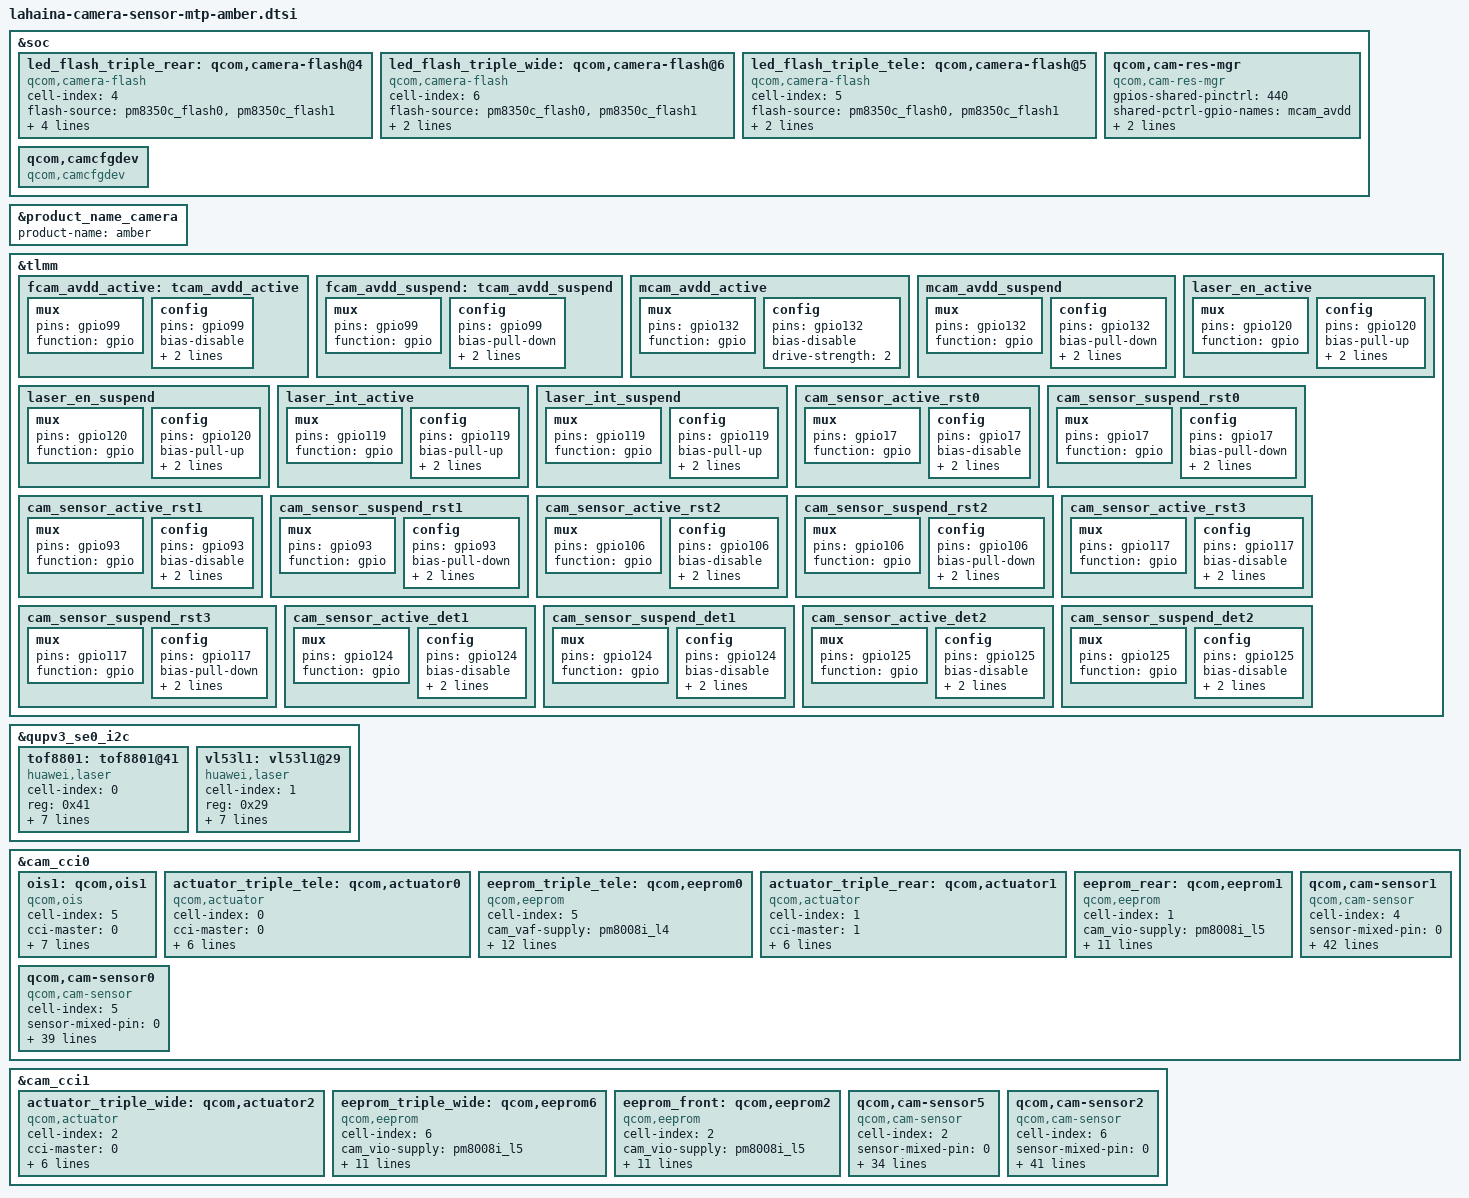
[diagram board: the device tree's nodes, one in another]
#include <dt-bindings/clock/qcom,camcc-lahaina.h>

&soc {
	led_flash_triple_rear: qcom,camera-flash@4 {
		cell-index = <4>;
		compatible = "qcom,camera-flash";
		flash-source = <&pm8350c_flash0 &pm8350c_flash1>;
		torch-source = <&pm8350c_torch0 &pm8350c_torch1>;
		switch-source = <&pm8350c_switch2>;
		torch-light-num = <0 1>;
		torch-light-name = "torch-light0", "torch-light1";
		status = "ok";
	};

	led_flash_triple_wide: qcom,camera-flash@6 {
		cell-index = <6>;
		compatible = "qcom,camera-flash";
		flash-source = <&pm8350c_flash0 &pm8350c_flash1>;
		torch-source = <&pm8350c_torch0 &pm8350c_torch1>;
		switch-source = <&pm8350c_switch2>;
		status = "ok";
	};

	led_flash_triple_tele: qcom,camera-flash@5 {
		cell-index = <5>;
		compatible = "qcom,camera-flash";
		flash-source = <&pm8350c_flash0 &pm8350c_flash1>;
		torch-source = <&pm8350c_torch0 &pm8350c_torch1>;
		switch-source = <&pm8350c_switch2>;
		status = "ok";
	};

    qcom,cam-res-mgr {
         compatible = "qcom,cam-res-mgr";
         gpios-shared-pinctrl = <440>;
         shared-pctrl-gpio-names = "mcam_avdd";
         pinctrl-names = "mcam_avdd_active", "mcam_avdd_suspend";
         pinctrl-0 = <&mcam_avdd_active>;
         pinctrl-1 = <&mcam_avdd_suspend>;
         status = "ok";
    };

	qcom,camcfgdev {
		compatible = "qcom,camcfgdev";
		status = "ok";
	};
};

&product_name_camera {
    product-name = "amber";
};

&tlmm {
	fcam_avdd_active: tcam_avdd_active {
		/* AVDD for font */
		mux {
			pins = "gpio99";
			function = "gpio";
		};

		config {
			pins = "gpio99";
			bias-disable; /* No PULL */
			drive-strength = <2>; /* 2 MA */
			output-high;
		};
	};

	fcam_avdd_suspend: tcam_avdd_suspend {
		/* AVDD for font */
		mux {
			pins = "gpio99";
			function = "gpio";
		};

		config {
			pins = "gpio99";
			bias-pull-down; /* PULL DOWN */
			drive-strength = <2>; /* 2 MA */
			output-low;
		};
	};
	mcam_avdd_active: mcam_avdd_active {
		/* mcam_avdd */
		mux {
			pins = "gpio132";
			function = "gpio";
		};

		config {
			pins = "gpio132";
			bias-disable; /* No PULL */
			drive-strength = <2>; /* 2 MA */
		};
	};

	mcam_avdd_suspend: mcam_avdd_suspend {
		/* mcam_avdd */
		mux {
			pins = "gpio132";
			function = "gpio";
		};

		config {
			pins = "gpio132";
			bias-pull-down; /* PULL DOWN */
			drive-strength = <2>; /* 2 MA */
			output-low;
		};
	};

	laser_en_active: laser_en_active {
		/* laser en pin */
		mux {
			pins = "gpio120";
			function = "gpio";
		};

		config {
			pins = "gpio120";
			bias-pull-up; /* PULL UP */
			drive-strength = <2>; /* 2 MA */
			input-enable;
		};
	};

	laser_en_suspend: laser_en_suspend {
		/* laser en pin */
		mux {
			pins = "gpio120";
			function = "gpio";
		};

		config {
			pins = "gpio120";
			bias-pull-up; /* PULL UP */
			drive-strength = <2>; /* 2 MA */
			input-enable;
		};
	};

	laser_int_active: laser_int_active {
		/* laser int pin */
		mux {
			pins = "gpio119";
			function = "gpio";
		};

		config {
			pins = "gpio119";
			bias-pull-up; /* PULL UP */
			drive-strength = <2>; /* 2 MA */
			input-enable;
		};
	};

	laser_int_suspend: laser_int_suspend {
		/* laser int pin */
		mux {
			pins = "gpio119";
			function = "gpio";
		};

		config {
			pins = "gpio119";
			bias-pull-up; /* PULL UP */
			drive-strength = <2>; /* 2 MA */
			input-enable;
		};
	};

	cam_sensor_active_rst0: cam_sensor_active_rst0 {
		/* RESET REAR */
		mux {
			pins = "gpio17";
			function = "gpio";
		};

		config {
			pins = "gpio17";
			bias-disable; /* No PULL */
			drive-strength = <2>; /* 2 MA */
			input-enable;
		};
	};

	cam_sensor_suspend_rst0: cam_sensor_suspend_rst0 {
		/* RESET REAR */
		mux {
			pins = "gpio17";
			function = "gpio";
		};

		config {
			pins = "gpio17";
			bias-pull-down; /* PULL DOWN */
			drive-strength = <2>; /* 2 MA */
			output-low;
		};
	};

	cam_sensor_active_rst1: cam_sensor_active_rst1 {
		/* RESET REARAUX */
		mux {
			pins = "gpio93";
			function = "gpio";
		};

		config {
			pins = "gpio93";
			bias-disable; /* No PULL */
			drive-strength = <2>; /* 2 MA */
			input-enable;
		};
	};

	cam_sensor_suspend_rst1: cam_sensor_suspend_rst1 {
		/* RESET REARAUX */
		mux {
			pins = "gpio93";
			function = "gpio";
		};

		config {
			pins = "gpio93";
			bias-pull-down; /* PULL DOWN */
			drive-strength = <2>; /* 2 MA */
			output-low;
		};
	};

	cam_sensor_active_rst2: cam_sensor_active_rst2 {
		/* RESET 2 */
		mux {
			pins = "gpio106";
			function = "gpio";
		};

		config {
			pins = "gpio106";
			bias-disable; /* No PULL */
			drive-strength = <2>; /* 2 MA */
			input-enable;
		};
	};

	cam_sensor_suspend_rst2: cam_sensor_suspend_rst2 {
		/* RESET 2 */
		mux {
			pins = "gpio106";
			function = "gpio";
		};

		config {
			pins = "gpio106";
			bias-pull-down; /* PULL DOWN */
			drive-strength = <2>; /* 2 MA */
			output-low;
		};
	};

	cam_sensor_active_rst3: cam_sensor_active_rst3 {
		/* RESET 3 */
		mux {
			pins = "gpio117";
			function = "gpio";
		};

		config {
			pins = "gpio117";
			bias-disable; /* No PULL */
			drive-strength = <2>; /* 2 MA */
			input-enable;
		};
	};

	cam_sensor_suspend_rst3: cam_sensor_suspend_rst3 {
		/* RESET 3 */
		mux {
			pins = "gpio117";
			function = "gpio";
		};

		config {
			pins = "gpio117";
			bias-pull-down; /* PULL DOWN */
			drive-strength = <2>; /* 2 MA */
			output-low;
		};
	};

	cam_sensor_active_det1: cam_sensor_active_det1 {
		/* BTB_DET 1 */
		mux {
			pins = "gpio124";
			function = "gpio";
		};

		config {
			pins = "gpio124";
			bias-disable; /* No PULL */
			drive-strength = <2>; /* 2 MA */
			input-enable;
		};
	};

	cam_sensor_suspend_det1: cam_sensor_suspend_det1 {
		/* BTB_DET 1 */
		mux {
			pins = "gpio124";
			function = "gpio";
		};

		config {
			pins = "gpio124";
			bias-disable; /* No PULL */
			drive-strength = <2>; /* 2 MA */
			input-enable;
		};
	};

	cam_sensor_active_det2: cam_sensor_active_det2 {
		/* BTB_DET 2 */
		mux {
			pins = "gpio125";
			function = "gpio";
		};

		config {
			pins = "gpio125";
			bias-disable; /* No PULL */
			drive-strength = <2>; /* 2 MA */
			input-enable;
		};
	};

	cam_sensor_suspend_det2: cam_sensor_suspend_det2 {
		/* BTB_DET 2 */
		mux {
			pins = "gpio125";
			function = "gpio";
		};

		config {
			pins = "gpio125";
			bias-disable; /* No PULL */
			drive-strength = <2>; /* 2 MA */
			input-enable;
		};
	};
};

/* laser */
&qupv3_se0_i2c {
	status = "ok";

	tof8801: tof8801@41 {
		cell-index = <0>;
		compatible = "huawei,laser";
		reg = <0x41>;
		vdd_ana-supply = <&pm8350_l7>;
		gpios = <&tlmm 120 0>,
			<&tlmm 119 0>;
		pinctrl-names = "laser_int_active", "laser_en_active";
		pinctrl-0 = <&laser_int_active>;
		pinctrl-1 = <&laser_en_active>;
		gpio-req-tbl-num = <0>;
		gpio-req-tbl-flags = <0>;
		gpio-req-tbl-label = "CAM_VAF0";
		status = "ok";
	};

	vl53l1: vl53l1@29 {
		cell-index = <1>;
		compatible = "huawei,laser";
		reg = <0x29>;
		vdd_ana-supply = <&pm8350_l7>;
		gpios = <&tlmm 120 0>,
			<&tlmm 119 0>;
		pinctrl-names = "laser_int_active", "laser_en_active";
		pinctrl-0 = <&laser_int_active>;
		pinctrl-1 = <&laser_en_active>;
		gpio-req-tbl-num = <0>;
		gpio-req-tbl-flags = <0>;
		gpio-req-tbl-label = "CAM_VAF0";
		status = "ok";
	};
};

/* cci0: i2c0 i2c1 */
&cam_cci0 {

	ois1: qcom,ois1 {
		cell-index = <5>;
		compatible = "qcom,ois";
		cci-master = <0>;
		cam_vio-supply = <&pm8008i_l5>;
		cam_vaf-supply = <&pm8008i_l4>;
		regulator-names = "cam_vio", "cam_vaf";
		rgltr-cntrl-support;
		rgltr-min-voltage = <1800000 3200000>;
		rgltr-max-voltage = <1900000 3200000>;
		rgltr-load-current = <74000 103000>;
	};

	actuator_triple_tele: qcom,actuator0 {
		cell-index = <0>;
		compatible = "qcom,actuator";
		cci-master = <0>;
		cam_vaf-supply = <&pm8008i_l4>;
		regulator-names = "cam_vaf";
		rgltr-cntrl-support;
		rgltr-min-voltage = <3200000>;
		rgltr-max-voltage = <3200000>;
		rgltr-load-current = <103000>;
	};

	eeprom_triple_tele: qcom,eeprom0 {
		cell-index = <5>;
		compatible = "qcom,eeprom";
		cam_vaf-supply = <&pm8008i_l4>;
		cam_vio-supply = <&pm8008i_l5>;
		cam_clk-supply = <&cam_cc_titan_top_gdsc>;
		regulator-names = "cam_vaf", "cam_vio", "cam_clk";
		rgltr-cntrl-support;
		rgltr-min-voltage = <3200000 1800000 0>;
		rgltr-max-voltage = <3200000 1900000 0>;
		rgltr-load-current = <103000 74000 0>;
		gpio-no-mux = <0>;
		cci-master = <0>;
		status = "ok";
		clocks = <&clock_camcc CAM_CC_MCLK0_CLK>;
		clock-names = "cam_clk";
		clock-cntl-level = "nominal";
		clock-rates = <19200000>;
	};

	actuator_triple_rear: qcom,actuator1 {
		cell-index = <1>;
		compatible = "qcom,actuator";
		cci-master = <1>;
		cam_vaf-supply = <&pm8008i_l4>;
		regulator-names = "cam_vaf";
		rgltr-cntrl-support;
		rgltr-min-voltage = <3200000>;
		rgltr-max-voltage = <3200000>;
		rgltr-load-current = <103000>;
	};

	eeprom_rear: qcom,eeprom1 {
		cell-index = <1>;
		compatible = "qcom,eeprom";
		cam_vio-supply = <&pm8008i_l5>;
		cam_clk-supply = <&cam_cc_titan_top_gdsc>;
		regulator-names = "cam_vio", "cam_clk";
		rgltr-cntrl-support;
		rgltr-min-voltage = <1800000 0>;
		rgltr-max-voltage = <1800000 0>;
		rgltr-load-current = <74000 0>;
		gpio-no-mux = <0>;
		cci-master = <1>; /* i2c1 */
		status = "ok";
		clocks = <&clock_camcc CAM_CC_MCLK1_CLK>;
		clock-names = "cam_clk";
		clock-cntl-level = "nominal";
		clock-rates = <19200000>;
	};

	/* main imx766 */
	qcom,cam-sensor1 {
		cell-index = <4>; /* slotId 4 */
		compatible = "qcom,cam-sensor";
		sensor-mixed-pin = <0>;
		csiphy-sd-index = <1>; /* cphy1 */
		sensor-position-roll = <90>;
		sensor-position-pitch = <0>;
		sensor-position-yaw = <180>;
		actuator-src = <&actuator_triple_rear>;
		eeprom-src = <&eeprom_rear>;
		led-flash-src = <&led_flash_triple_rear>;
		cam_vio-supply = <&pm8008i_l5>; /* iovdd pm8008 l5 1.8v */
		cam_vana-supply = <&pm8008i_l6>; /* avdd0 pm8008 l6 2.85v */
		cam_vdig-supply = <&pm8008i_l1>; /* dvdd pm8008 l1 1.14v */
		cam_v_custom1-supply = <&pm8008i_l4>; /* afvdd pm8008 l4 3.2v, need to check */
		cam_clk-supply = <&cam_cc_titan_top_gdsc>;
		regulator-names = "cam_vio", "cam_vana", "cam_vdig", "cam_v_custom1",
			"cam_clk";
		rgltr-cntrl-support;
		rgltr-min-voltage = <1800000 2850000 1140000 3200000 0>;
		rgltr-max-voltage = <1900000 2900000 1200000 3200000 0>;
		rgltr-load-current = <805000 52000 805000 805000 0>;
		gpio-no-mux = <0>;
		pinctrl-names = "cam_default", "cam_suspend";
		pinctrl-0 = <&cam_sensor_mclk1_active
				&cam_sensor_active_rst1
				&cam_sensor_active_det1>;
		pinctrl-1 = <&cam_sensor_mclk1_suspend
				&cam_sensor_suspend_rst1
				&cam_sensor_suspend_det1>;
		gpios = <&tlmm 101 0>, /* mclk1 gpio101 */
			<&tlmm 93 0>, /* rst gpio93 */
			<&tlmm 132 0>, /* avdd gpio132 */
			<&tlmm 124 0>; /* det gpio124 */
		gpio-reset = <1>;
		gpio-mixed1 = <2>;
		gpio-btb-det = <3>;
		gpio-req-tbl-num = <0 1 2 3>;
		gpio-req-tbl-flags = <1 0 0 0>;
		gpio-req-tbl-label = "CAMIF_MCLK1",
					"CAM_RESET1",
					"CAM_MIXED_GPIO",
					"CAM_BTB_DET1";
		cci-master = <1>; /* i2c1 */
		status = "ok";
		clocks = <&clock_camcc CAM_CC_MCLK1_CLK>;
		clock-names = "cam_clk";
		clock-cntl-level = "nominal";
		clock-rates = <19200000>;
		ic_position = <0>; /* CAMERA_POSITION_REAR */
		btb_check = <1>; /* need btb check */
	};

	/* tele c029oby imx351 */
	qcom,cam-sensor0 {
		cell-index = <5>; /* slotId 5 */
		compatible = "qcom,cam-sensor";
		sensor-mixed-pin = <0>;
		csiphy-sd-index = <0>;
		sensor-position-roll = <90>;
		sensor-position-pitch = <0>;
		sensor-position-yaw = <180>;
		actuator-src = <&actuator_triple_tele>;
		eeprom-src = <&eeprom_triple_tele>;
		ois-src  = <&ois1>;
		led-flash-src = <&led_flash_triple_tele>;
		cam_vio-supply = <&pm8008i_l5>; /* iovdd pm8008 l5 1.8v */
		cam_vana-supply = <&pm8008i_l3>; /* avdd pm8008 l3 2.85v */
		cam_v_custom1-supply = <&pm8008i_l4>; /* afvdd pm8008 l4 3.2v, need to check */
		cam_vdig-supply = <&pm8008i_l2>; /* dvdd pm8008 l2 1.14v */
		cam_clk-supply = <&cam_cc_titan_top_gdsc>;
		regulator-names = "cam_vio", "cam_vana", "cam_v_custom1",
			"cam_vdig","cam_clk";
		rgltr-cntrl-support;
		rgltr-min-voltage = <1800000 2850000 3200000 1140000 0>;
		rgltr-max-voltage = <1800000 3000000 3200000 1200000 0>;
		rgltr-load-current = <5000 68000 74000 805000 0>;
		gpio-no-mux = <0>;
		pinctrl-names = "cam_default", "cam_suspend";
		pinctrl-0 = <&cam_sensor_mclk0_active
				&cam_sensor_active_rst3>;
		pinctrl-1 = <&cam_sensor_mclk0_suspend
				&cam_sensor_suspend_rst3>;
		gpios = <&tlmm 100 0>,
			<&tlmm 117 0>,
			<&tlmm 132 0>; /* avdd gpio132 */
		gpio-reset = <1>;
		gpio-mixed1 = <2>;
		gpio-req-tbl-num = <0 1 2>;
		gpio-req-tbl-flags = <1 0 0>;
		gpio-req-tbl-label = "CAMIF_MCLK0",
					"CAM_RESET3",
					"CAM_MIXED_GPIO";
		cci-master = <0>;
		status = "ok";
		clocks = <&clock_camcc CAM_CC_MCLK0_CLK>;
		clock-names = "cam_clk";
		clock-cntl-level = "nominal";
		clock-rates = <19200000>;
		ic_position = <4>; /* CAMERA_POSITION_REAR_THIRD */
		btb_check = <1>; /* need btb check */
	};

};

&cam_cci1 {

	actuator_triple_wide: qcom,actuator2 {
		cell-index = <2>;
		compatible = "qcom,actuator";
		cci-master = <0>;
		cam_vaf-supply = <&pm8008i_l4>;
		regulator-names = "cam_vaf";
		rgltr-cntrl-support;
		rgltr-min-voltage = <3200000>;
		rgltr-max-voltage = <3200000>;
		rgltr-load-current = <103000>;
	};

	eeprom_triple_wide: qcom,eeprom6 {
		cell-index = <6>;
		compatible = "qcom,eeprom";
		cam_vio-supply = <&pm8008i_l5>;
		cam_clk-supply = <&cam_cc_titan_top_gdsc>;
		regulator-names = "cam_vio", "cam_clk";
		rgltr-cntrl-support;
		rgltr-min-voltage = <1800000 0>;
		rgltr-max-voltage = <1800000 0>;
		rgltr-load-current = <74000 0>;
		gpio-no-mux = <0>;
		cci-master = <0>;
		status = "ok";
		clocks = <&clock_camcc CAM_CC_MCLK2_CLK>;
		clock-names = "cam_clk";
		clock-cntl-level = "nominal";
		clock-rates = <19200000>;
	};

	eeprom_front: qcom,eeprom2 {
		cell-index = <2>;
		compatible = "qcom,eeprom";
		cam_vio-supply = <&pm8008i_l5>;
		cam_clk-supply = <&cam_cc_titan_top_gdsc>;
		regulator-names = "cam_vio", "cam_clk";
		rgltr-cntrl-support;
		rgltr-min-voltage = <1800000 0>;
		rgltr-max-voltage = <1800000 0>;
		rgltr-load-current = <74000 0>;
		gpio-no-mux = <0>;
		cci-master = <1>;
		status = "ok";
		clocks = <&clock_camcc CAM_CC_MCLK5_CLK>;
		clock-names = "cam_clk";
		clock-cntl-level = "nominal";
		clock-rates = <19200000>;
	};

	qcom,cam-sensor5 {
		cell-index = <2>; /* slotId 2 */
		compatible = "qcom,cam-sensor";
		sensor-mixed-pin = <0>;
		csiphy-sd-index = <5>; /* phy5 */
		sensor-position-roll = <270>;
		sensor-position-pitch = <0>;
		sensor-position-yaw = <0>;
		eeprom-src = <&eeprom_front>;
		cam_vio-supply = <&pm8008i_l5>; /* iovdd pm8008 l5 1.8v */
		cam_vana-supply = <&pm8008i_l3>; /* avdd pm8008 l3 2.85v */
		cam_vdig-supply = <&pm8008i_l1>; /* dvdd pm8008 l1 1.14v */
		cam_clk-supply = <&cam_cc_titan_top_gdsc>;
		regulator-names = "cam_vio", "cam_vana", "cam_vdig",
			"cam_clk";
		rgltr-cntrl-support;
		rgltr-min-voltage = <1800000 2850000 1140000 0>;
		rgltr-max-voltage = <1800000 2900000 1200000 0>;
		rgltr-load-current = <3000 52000 805000 0>;
		gpio-no-mux = <0>;
		pinctrl-names = "cam_default", "cam_suspend";
		pinctrl-0 = <&cam_sensor_mclk5_active
				 &fcam_avdd_active
				 &cam_sensor_active_rst0>;
		pinctrl-1 = <&cam_sensor_mclk5_suspend
				 &fcam_avdd_suspend
				 &cam_sensor_suspend_rst0>;
		gpios = <&tlmm 105 0>,
			<&tlmm 17 0>,
			<&tlmm 132 0>, /* avdd gpio132 */
			<&tlmm 72 0>; /* pove gpio72 */
		gpio-reset = <1>;
		gpio-mixed1 = <2>;
		gpio-custom1 = <3>;
		gpio-req-tbl-num = <0 1 2 3>;
		gpio-req-tbl-flags = <1 0 0 0>;
		gpio-req-tbl-label = "CAMIF_MCLK5",
					"CAM_RESET0",
					"CAM_MIXED_GPIO",
					"CAM_CUSTOM1";
		cci-master = <1>;
		status = "ok";
		clocks = <&clock_camcc CAM_CC_MCLK5_CLK>;
		clock-names = "cam_clk";
		clock-cntl-level = "nominal";
		clock-rates = <19200000>;
		ic_position = <1>; /* CAMERA_POSITION_FORE */
		btb_check = <1>; /* need btb check */
	};

	qcom,cam-sensor2 {
		cell-index = <6>;
		compatible = "qcom,cam-sensor";
		sensor-mixed-pin = <0>;
		csiphy-sd-index = <2>;
		sensor-position-roll = <90>;
		sensor-position-pitch = <0>;
		sensor-position-yaw = <180>;
		actuator-src = <&actuator_triple_wide>;
		eeprom-src = <&eeprom_triple_wide>;
		led-flash-src = <&led_flash_triple_wide>;
		cam_vio-supply = <&pm8008i_l5>; /* iovdd pm8008 l5 1.8v */
		cam_vana-supply = <&pm8008i_l7>; /* avdd pm8008 l7 2.85v */
		cam_vdig-supply = <&pm8008i_l2>; /* dvdd pm8008 l2 1.14v */
		cam_v_custom1-supply = <&pm8008i_l4>; /* afvdd pm8008 l4 3.2v, need to check */
		cam_clk-supply = <&cam_cc_titan_top_gdsc>;
		regulator-names = "cam_vio", "cam_vana", "cam_v_custom1",
			"cam_vdig","cam_clk";
		rgltr-cntrl-support;
		rgltr-min-voltage = <1800000 2850000 3200000 1140000 0>;
		rgltr-max-voltage = <1800000 3000000 3200000 1200000 0>;
		rgltr-load-current = <5000 68000 74000 805000 0>;
		gpio-no-mux = <0>;
		pinctrl-names = "cam_default", "cam_suspend";
		pinctrl-0 = <&cam_sensor_mclk2_active
				 &cam_sensor_active_rst2
				 &cam_sensor_active_det2>;
		pinctrl-1 = <&cam_sensor_mclk2_suspend
				 &cam_sensor_suspend_rst2
				 &cam_sensor_suspend_det2>;
		gpios = <&tlmm 102 0>,
			<&tlmm 106 0>,
			<&tlmm 132 0>, /* avdd gpio132 */
			<&tlmm 125 0>; /* det gpio125 */
		gpio-reset = <1>;
		gpio-mixed1 = <2>;
		gpio-btb-det = <3>;
		gpio-req-tbl-num = <0 1 2 3>;
		gpio-req-tbl-flags = <1 0 0 0>;
		gpio-req-tbl-label = "CAMIF_MCLK2",
					"CAM_RESET2",
					"CAM_MIXED_GPIO",
					"CAM_BTB_DET2";
		cci-master = <0>;
		status = "ok";
		clocks = <&clock_camcc CAM_CC_MCLK2_CLK>;
		clock-names = "cam_clk";
		clock-cntl-level = "nominal";
		clock-rates = <19200000>;
		ic_position = <2>; /* CAMERA_POSITION_REAR_SECOND */
		btb_check = <1>; /* need btb check */
	};

};
